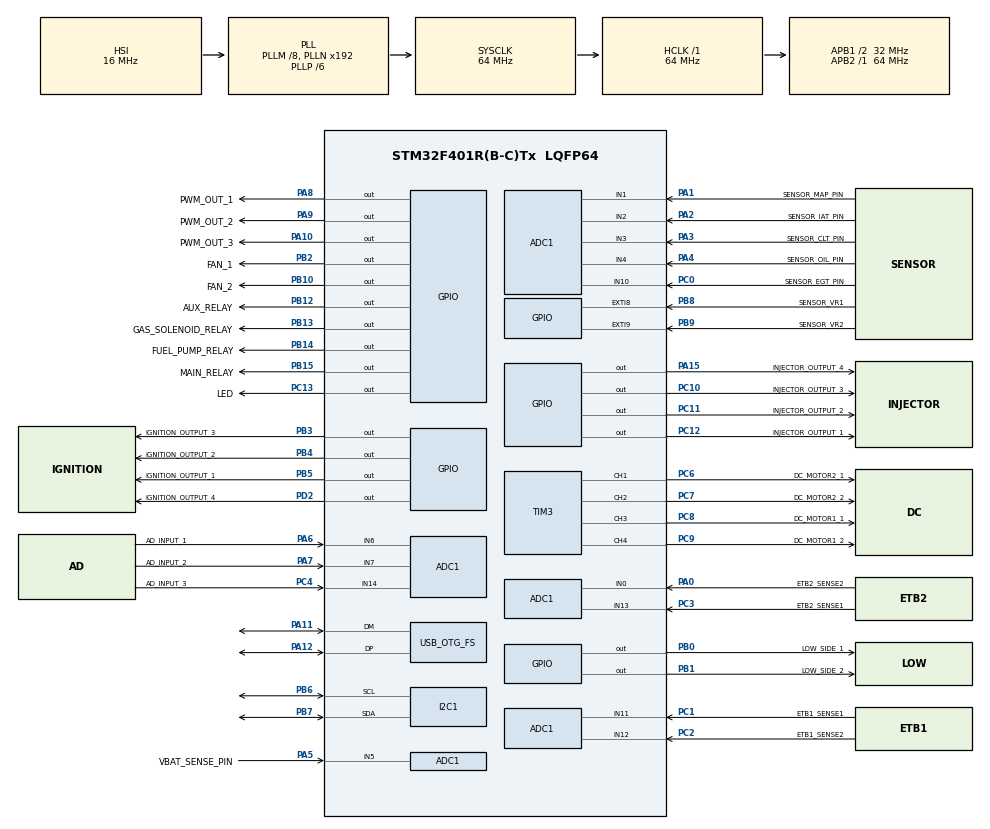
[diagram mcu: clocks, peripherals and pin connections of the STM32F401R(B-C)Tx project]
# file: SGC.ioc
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ADC1.Channel-10\#ChannelRegularConversion=ADC_CHANNEL_0
ADC1.Channel-11\#ChannelRegularConversion=ADC_CHANNEL_1
ADC1.Channel-12\#ChannelRegularConversion=ADC_CHANNEL_2
ADC1.Channel-13\#ChannelRegularConversion=ADC_CHANNEL_3
ADC1.Channel-14\#ChannelRegularConversion=ADC_CHANNEL_4
ADC1.Channel-15\#ChannelRegularConversion=ADC_CHANNEL_5
ADC1.Channel-16\#ChannelRegularConversion=ADC_CHANNEL_6
ADC1.Channel-17\#ChannelRegularConversion=ADC_CHANNEL_7
ADC1.Channel-18\#ChannelRegularConversion=ADC_CHANNEL_14
ADC1.Channel-19\#ChannelInjectedConversion=ADC_CHANNEL_11
ADC1.Channel-20\#ChannelInjectedConversion=ADC_CHANNEL_12
ADC1.Channel-21\#ChannelInjectedConversion=ADC_CHANNEL_13
ADC1.Channel-22\#ChannelInjectedConversion=ADC_CHANNEL_0
ADC1.Channel-4\#ChannelRegularConversion=ADC_CHANNEL_10
ADC1.Channel-5\#ChannelRegularConversion=ADC_CHANNEL_11
ADC1.Channel-6\#ChannelRegularConversion=ADC_CHANNEL_12
ADC1.Channel-7\#ChannelRegularConversion=ADC_CHANNEL_13
ADC1.ContinuousConvMode=DISABLE
ADC1.DMAContinuousRequests=ENABLE
ADC1.EOCSelection=ADC_EOC_SEQ_CONV
ADC1.EnableAnalogWatchDog=false
ADC1.ExternalTrigConv=ADC_EXTERNALTRIGCONV_T5_CC1
ADC1.ExternalTrigInjecConv=ADC_INJECTED_SOFTWARE_START
ADC1.InjNumberOfConversion=4
ADC1.InjectedConvMode=AutoInjected
ADC1.InjectedOffset-19\#ChannelInjectedConversion=0
ADC1.InjectedOffset-20\#ChannelInjectedConversion=0
ADC1.InjectedOffset-21\#ChannelInjectedConversion=0
ADC1.InjectedOffset-22\#ChannelInjectedConversion=0
ADC1.InjectedRank-19\#ChannelInjectedConversion=1
ADC1.InjectedRank-20\#ChannelInjectedConversion=2
ADC1.InjectedRank-21\#ChannelInjectedConversion=3
ADC1.InjectedRank-22\#ChannelInjectedConversion=4
ADC1.NbrOfConversion=13
ADC1.NbrOfConversionFlag=1
ADC1.Rank-10\#ChannelRegularConversion=5
ADC1.Rank-11\#ChannelRegularConversion=6
ADC1.Rank-12\#ChannelRegularConversion=7
ADC1.Rank-13\#ChannelRegularConversion=8
ADC1.Rank-14\#ChannelRegularConversion=9
ADC1.Rank-15\#ChannelRegularConversion=10
ADC1.Rank-16\#ChannelRegularConversion=11
ADC1.Rank-17\#ChannelRegularConversion=12
ADC1.Rank-18\#ChannelRegularConversion=13
ADC1.Rank-4\#ChannelRegularConversion=1
ADC1.Rank-5\#ChannelRegularConversion=2
ADC1.Rank-6\#ChannelRegularConversion=3
ADC1.Rank-7\#ChannelRegularConversion=4
ADC1.SamplingTime-10\#ChannelRegularConversion=ADC_SAMPLETIME_3CYCLES
ADC1.SamplingTime-11\#ChannelRegularConversion=ADC_SAMPLETIME_3CYCLES
ADC1.SamplingTime-12\#ChannelRegularConversion=ADC_SAMPLETIME_3CYCLES
ADC1.SamplingTime-13\#ChannelRegularConversion=ADC_SAMPLETIME_3CYCLES
ADC1.SamplingTime-14\#ChannelRegularConversion=ADC_SAMPLETIME_3CYCLES
ADC1.SamplingTime-15\#ChannelRegularConversion=ADC_SAMPLETIME_3CYCLES
ADC1.SamplingTime-16\#ChannelRegularConversion=ADC_SAMPLETIME_3CYCLES
ADC1.SamplingTime-17\#ChannelRegularConversion=ADC_SAMPLETIME_3CYCLES
ADC1.SamplingTime-18\#ChannelRegularConversion=ADC_SAMPLETIME_3CYCLES
ADC1.SamplingTime-19\#ChannelInjectedConversion=ADC_SAMPLETIME_3CYCLES
ADC1.SamplingTime-20\#ChannelInjectedConversion=ADC_SAMPLETIME_3CYCLES
ADC1.SamplingTime-21\#ChannelInjectedConversion=ADC_SAMPLETIME_3CYCLES
ADC1.SamplingTime-22\#ChannelInjectedConversion=ADC_SAMPLETIME_3CYCLES
ADC1.SamplingTime-4\#ChannelRegularConversion=ADC_SAMPLETIME_84CYCLES
ADC1.SamplingTime-5\#ChannelRegularConversion=ADC_SAMPLETIME_3CYCLES
ADC1.SamplingTime-6\#ChannelRegularConversion=ADC_SAMPLETIME_3CYCLES
ADC1.SamplingTime-7\#ChannelRegularConversion=ADC_SAMPLETIME_3CYCLES
ADC1.master=1
Dma.ADC1.0.Direction=DMA_PERIPH_TO_MEMORY
Dma.ADC1.0.FIFOMode=DMA_FIFOMODE_DISABLE
Dma.ADC1.0.Instance=DMA2_Stream0
Dma.ADC1.0.MemDataAlignment=DMA_MDATAALIGN_HALFWORD
Dma.ADC1.0.MemInc=DMA_MINC_ENABLE
Dma.ADC1.0.Mode=DMA_CIRCULAR
Dma.ADC1.0.PeriphDataAlignment=DMA_PDATAALIGN_HALFWORD
Dma.ADC1.0.PeriphInc=DMA_PINC_DISABLE
Dma.ADC1.0.Priority=DMA_PRIORITY_HIGH
Dma.Request0=ADC1
FREERTOS.Events01=engine_flags,Static,engine_flagsControlBlock
FREERTOS.Tasks01=defaultTask,48,512,StartDefaultTask,Default,NULL,Dynamic,NULL,NULL;init_task,48,1024,controller_init_task,Default,NULL,Dynamic,NULL,NULL
FREERTOS.configENABLE_FPU=1
Mcu.Family=STM32F4
Mcu.Name=STM32F401R(B-C)Tx
Mcu.Package=LQFP64
NVIC.DMA2_Stream0_IRQn=true\:7\:0\:true\:false\:true\:true\:false\:true\:true
NVIC.EXTI9_5_IRQn=true\:5\:0\:true\:false\:true\:true\:true\:true\:true
NVIC.OTG_FS_IRQn=true\:7\:0\:true\:false\:true\:true\:false\:true\:true
NVIC.PriorityGroup=NVIC_PRIORITYGROUP_4
NVIC.TIM1_TRG_COM_TIM11_IRQn=true\:15\:0\:false\:false\:true\:false\:false\:true\:true
NVIC.TIM2_IRQn=true\:6\:0\:true\:false\:true\:true\:true\:true\:true
NVIC.TimeBase=TIM1_TRG_COM_TIM11_IRQn
NVIC.TimeBaseIP=TIM11
PA0-WKUP.GPIO_Label=ETB2_SENSE2
PA0-WKUP.Signal=ADCx_IN0
PA1.GPIO_Label=SENSOR_MAP_PIN
PA1.Signal=ADCx_IN1
PA10.GPIO_Label=PWM_OUT_3
PA10.Signal=GPIO_Output
PA11.Mode=Device_Only
PA11.Signal=USB_OTG_FS_DM
PA12.Mode=Device_Only
PA12.Signal=USB_OTG_FS_DP
PA13.Mode=Serial_Wire
PA13.Signal=SYS_JTMS-SWDIO
PA14.Mode=Serial_Wire
PA14.Signal=SYS_JTCK-SWCLK
PA15.GPIO_Label=INJECTOR_OUTPUT_4
PA15.GPIO_PuPd=GPIO_NOPULL
PA15.GPIO_Speed=GPIO_SPEED_FREQ_MEDIUM
PA15.PinState=GPIO_PIN_RESET
PA15.Signal=GPIO_Output
PA2.GPIO_Label=SENSOR_IAT_PIN
PA2.Signal=ADCx_IN2
PA3.GPIO_Label=SENSOR_CLT_PIN
PA3.Signal=ADCx_IN3
PA4.GPIO_Label=SENSOR_OIL_PIN
PA4.Signal=ADCx_IN4
PA5.GPIO_Label=VBAT_SENSE_PIN
PA5.Signal=ADCx_IN5
PA6.GPIO_Label=AD_INPUT_1
PA6.Signal=ADCx_IN6
PA7.GPIO_Label=AD_INPUT_2
PA7.Signal=ADCx_IN7
PA8.GPIO_Label=PWM_OUT_1
PA8.Signal=GPIO_Output
PA9.GPIO_Label=PWM_OUT_2
PA9.Signal=GPIO_Output
PB0.GPIO_Label=LOW_SIDE_1
PB0.Signal=GPIO_Output
PB1.GPIO_Label=LOW_SIDE_2
PB1.Signal=GPIO_Output
PB10.GPIO_Label=FAN_2
PB10.Signal=GPIO_Output
PB12.GPIO_Label=AUX_RELAY
PB12.Signal=GPIO_Output
PB13.GPIO_Label=GAS_SOLENOID_RELAY
PB13.Signal=GPIO_Output
PB14.GPIO_Label=FUEL_PUMP_RELAY
PB14.Signal=GPIO_Output
PB15.GPIO_Label=MAIN_RELAY
PB15.Signal=GPIO_Output
PB2.GPIO_Label=FAN_1
PB2.Signal=GPIO_Output
PB3.GPIO_Label=IGNITION_OUTPUT_3
PB3.Signal=GPIO_Output
PB4.GPIO_Label=IGNITION_OUTPUT_2
PB4.Signal=GPIO_Output
PB5.GPIO_Label=IGNITION_OUTPUT_1
PB5.Signal=GPIO_Output
PB6.Mode=I2C
PB6.Signal=I2C1_SCL
PB7.Mode=I2C
PB7.Signal=I2C1_SDA
PB8.GPIO_Label=SENSOR_VR1
PB8.GPIO_ModeDefaultEXTI=GPIO_MODE_IT_RISING_FALLING
PB8.GPIO_PuPd=GPIO_NOPULL
PB8.Signal=GPXTI8
PB9.GPIO_Label=SENSOR_VR2
PB9.GPIO_ModeDefaultEXTI=GPIO_MODE_IT_RISING_FALLING
PB9.GPIO_PuPd=GPIO_NOPULL
PB9.Signal=GPXTI9
PC0.GPIO_Label=SENSOR_EGT_PIN
PC0.Signal=ADCx_IN10
PC1.GPIO_Label=ETB1_SENSE1
PC1.Signal=ADCx_IN11
PC10.GPIO_Label=INJECTOR_OUTPUT_3
PC10.Signal=GPIO_Output
PC11.GPIO_Label=INJECTOR_OUTPUT_2
PC11.Signal=GPIO_Output
PC12.GPIO_Label=INJECTOR_OUTPUT_1
PC12.Signal=GPIO_Output
PC13-ANTI_TAMP.GPIO_Label=LED
PC13-ANTI_TAMP.Signal=GPIO_Output
PC2.GPIO_Label=ETB1_SENSE2
PC2.Signal=ADCx_IN12
PC3.GPIO_Label=ETB2_SENSE1
PC3.Signal=ADCx_IN13
PC4.GPIO_Label=AD_INPUT_3
PC4.Signal=ADCx_IN14
PC6.GPIO_Label=DC_MOTOR2_1
PC6.Signal=S_TIM3_CH1
PC7.GPIO_Label=DC_MOTOR2_2
PC7.Signal=S_TIM3_CH2
PC8.GPIO_Label=DC_MOTOR1_1
PC8.Signal=S_TIM3_CH3
PC9.GPIO_Label=DC_MOTOR1_2
PC9.Signal=S_TIM3_CH4
PD2.GPIO_Label=IGNITION_OUTPUT_4
PD2.Signal=GPIO_Output
PH0\ -\ OSC_IN.Mode=HSE-External-Oscillator
PH0\ -\ OSC_IN.Signal=RCC_OSC_IN
PH1\ -\ OSC_OUT.Mode=HSE-External-Oscillator
PH1\ -\ OSC_OUT.Signal=RCC_OSC_OUT
ProjectManager.HeapSize=0x200
ProjectManager.StackSize=0x400
ProjectManager.TargetToolchain=Makefile
RCC.48MHZClocksFreq_Value=48000000
RCC.AHBFreq_Value=64000000
RCC.APB1CLKDivider=RCC_HCLK_DIV2
RCC.APB1Freq_Value=32000000
RCC.APB1TimFreq_Value=64000000
RCC.APB2Freq_Value=64000000
RCC.APB2TimFreq_Value=64000000
RCC.CortexFreq_Value=64000000
RCC.HCLKFreq_Value=64000000
RCC.HSE_VALUE=25000000
RCC.HSI_VALUE=16000000
RCC.LSE_VALUE=32768
RCC.PLLM=8
RCC.PLLP=RCC_PLLP_DIV6
RCC.PLLQ=8
RCC.PLLSource=RCC_PLLSOURCE_HSI
RCC.PLLSourceVirtualString=RCC_PLLSOURCE_HSI
RCC.SYSCLKFreq_VALUE=64000000
RCC.SYSCLKSource=RCC_SYSCLKSOURCE_PLLCLK
RCC.VCOOutputFreq_Value=384000000
SH.ADCx_IN0.0=ADC1_IN0,IN0
SH.ADCx_IN1.0=ADC1_IN1,IN1
SH.ADCx_IN10.0=ADC1_IN10,IN10
SH.ADCx_IN11.0=ADC1_IN11,IN11
SH.ADCx_IN12.0=ADC1_IN12,IN12
SH.ADCx_IN13.0=ADC1_IN13,IN13
SH.ADCx_IN14.0=ADC1_IN14,IN14
SH.ADCx_IN2.0=ADC1_IN2,IN2
SH.ADCx_IN3.0=ADC1_IN3,IN3
SH.ADCx_IN4.0=ADC1_IN4,IN4
SH.ADCx_IN5.0=ADC1_IN5,IN5
SH.ADCx_IN6.0=ADC1_IN6,IN6
SH.ADCx_IN7.0=ADC1_IN7,IN7
SH.S_TIM3_CH1.0=TIM3_CH1,PWM Generation1 CH1
SH.S_TIM3_CH2.0=TIM3_CH2,PWM Generation2 CH2
SH.S_TIM3_CH3.0=TIM3_CH3,PWM Generation3 CH3
SH.S_TIM3_CH4.0=TIM3_CH4,PWM Generation4 CH4
TIM2.Channel-Output\ Compare1\ No\ Output=TIM_CHANNEL_1
TIM2.OC1Preload=DISABLE
TIM2.Prescaler=84-1
TIM3.Channel-PWM\ Generation1\ CH1=TIM_CHANNEL_1
TIM3.Channel-PWM\ Generation2\ CH2=TIM_CHANNEL_2
TIM3.Channel-PWM\ Generation3\ CH3=TIM_CHANNEL_3
TIM3.Channel-PWM\ Generation4\ CH4=TIM_CHANNEL_4
TIM5.Channel-Output\ Compare1\ No\ Output=TIM_CHANNEL_1
TIM5.OC1Preload=ENABLE
TIM5.OCMode_1=TIM_OCMODE_TOGGLE
TIM5.Prescaler=64-1
TIM5.TIM_MasterOutputTrigger=TIM_TRGO_OC1REF
USB_DEVICE.CLASS_NAME_FS=CDC
USB_DEVICE.MANUFACTURER_STRING=Alireza Eskandari
USB_DEVICE.PRODUCT_STRING_CDC_FS=Smart Generator Controller
USB_DEVICE.VirtualMode=Cdc
USB_DEVICE.VirtualModeFS=Cdc_FS
USB_OTG_FS.VirtualMode=Device_Only
VP_CRC_VS_CRC.Mode=CRC_Activate
VP_FREERTOS_VS_CMSIS_V2.Mode=CMSIS_V2
VP_SYS_VS_tim11.Mode=TIM11
VP_TIM2_VS_ClockSourceINT.Mode=Internal
VP_TIM2_VS_no_output1.Mode=Output Compare1 No Output
VP_TIM3_VS_ClockSourceINT.Mode=Internal
VP_TIM5_VS_ClockSourceINT.Mode=Internal
VP_TIM5_VS_no_output1.Mode=Output Compare1 No Output
VP_USB_DEVICE_VS_USB_DEVICE_CDC_FS.Mode=CDC_FS
board=custom

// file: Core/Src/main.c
/* USER CODE BEGIN Header */
/**
  ******************************************************************************
  * @file           : main.c
  * @brief          : Main program body
  ******************************************************************************
  * @attention
  *
  * Copyright (c) 2025 STMicroelectronics.
  * All rights reserved.
  *
  * This software is licensed under terms that can be found in the LICENSE file
  * in the root directory of this software component.
  * If no LICENSE file comes with this software, it is provided AS-IS.
  *
  ******************************************************************************
  */
/* USER CODE END Header */
#include "main.h"
#include "cmsis_os.h"
#include "adc.h"
#include "crc.h"
#include "dma.h"
#include "i2c.h"
#include "tim.h"
#include "usb_device.h"
#include "gpio.h"

/* USER CODE BEGIN Includes */

#include "controller.h"

/* USER CODE END Includes */

void SystemClock_Config(void);
void MX_FREERTOS_Init(void);

int main(void)
{

  /* USER CODE BEGIN 1 */
  /**
   * @todo we will move to a proper init system in the future, but for now we are going to a simple methode for providing the settings
   */
  /* USER CODE END 1 */

  /* MCU Configuration--------------------------------------------------------*/

  /* Reset of all peripherals, Initializes the Flash interface and the Systick. */
  HAL_Init();

  /* Configure the system clock */
  SystemClock_Config();

  /* Initialize all configured peripherals */
  MX_GPIO_Init();
  MX_DMA_Init();
  MX_TIM3_Init();
  MX_ADC1_Init();
  MX_TIM2_Init();
  MX_CRC_Init();
  MX_I2C1_Init();
  MX_TIM5_Init();

  /* Init scheduler */
  osKernelInitialize();

  /* Call init function for freertos objects (in cmsis_os2.c) */
  MX_FREERTOS_Init();

  /* Start scheduler */
  osKernelStart();

  /* We should never get here as control is now taken by the scheduler */

  /* Infinite loop */
  while (1)
  {

  }
}

void SystemClock_Config(void)
{
  RCC_OscInitTypeDef RCC_OscInitStruct = {0};
  RCC_ClkInitTypeDef RCC_ClkInitStruct = {0};

  /** Configure the main internal regulator output voltage
  */
  __HAL_RCC_PWR_CLK_ENABLE();
  __HAL_PWR_VOLTAGESCALING_CONFIG(PWR_REGULATOR_VOLTAGE_SCALE2);

  /** Initializes the RCC Oscillators according to the specified parameters
  * in the RCC_OscInitTypeDef structure.
  */
  RCC_OscInitStruct.OscillatorType = RCC_OSCILLATORTYPE_HSI;
  RCC_OscInitStruct.HSIState = RCC_HSI_ON;
  RCC_OscInitStruct.HSICalibrationValue = RCC_HSICALIBRATION_DEFAULT;
  RCC_OscInitStruct.PLL.PLLState = RCC_PLL_ON;
  RCC_OscInitStruct.PLL.PLLSource = RCC_PLLSOURCE_HSI;
  RCC_OscInitStruct.PLL.PLLM = 8;
  RCC_OscInitStruct.PLL.PLLN = 192;
  RCC_OscInitStruct.PLL.PLLP = RCC_PLLP_DIV6;
  RCC_OscInitStruct.PLL.PLLQ = 8;
  if (HAL_RCC_OscConfig(&RCC_OscInitStruct) != HAL_OK)
  {
    Error_Handler();
  }

  /** Initializes the CPU, AHB and APB buses clocks
  */
  RCC_ClkInitStruct.ClockType = RCC_CLOCKTYPE_HCLK|RCC_CLOCKTYPE_SYSCLK
                              |RCC_CLOCKTYPE_PCLK1|RCC_CLOCKTYPE_PCLK2;
  RCC_ClkInitStruct.SYSCLKSource = RCC_SYSCLKSOURCE_PLLCLK;
  RCC_ClkInitStruct.AHBCLKDivider = RCC_SYSCLK_DIV1;
  RCC_ClkInitStruct.APB1CLKDivider = RCC_HCLK_DIV2;
  RCC_ClkInitStruct.APB2CLKDivider = RCC_HCLK_DIV1;

  if (HAL_RCC_ClockConfig(&RCC_ClkInitStruct, FLASH_LATENCY_2) != HAL_OK)
  {
    Error_Handler();
  }
}

void HAL_TIM_PeriodElapsedCallback(TIM_HandleTypeDef *htim)
{
  if (htim->Instance == TIM11)
  {
    HAL_IncTick();
  }
}

void Error_Handler(void)
{
  __disable_irq();
  while (1)
  {
  }
}

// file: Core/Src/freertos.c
/* USER CODE BEGIN Header */
/**
  ******************************************************************************
  * File Name          : freertos.c
  * Description        : Code for freertos applications
  ******************************************************************************
  * @attention
  *
  * Copyright (c) 2025 STMicroelectronics.
  * All rights reserved.
  *
  * This software is licensed under terms that can be found in the LICENSE file
  * in the root directory of this software component.
  * If no LICENSE file comes with this software, it is provided AS-IS.
  *
  ******************************************************************************
  */
/* USER CODE END Header */

#include "FreeRTOS.h"
#include "task.h"
#include "main.h"
#include "cmsis_os.h"

/* USER CODE BEGIN Includes */
#include "controller.h"
#include "trigger_simulator.h"
#include "utils.h"
/* USER CODE END Includes */

typedef StaticEventGroup_t osStaticEventGroupDef_t;

/* USER CODE BEGIN Variables */

table_2d_t test_table = {0};
float table_value = 0.0f;
/* USER CODE END Variables */
/* Definitions for defaultTask */
osThreadId_t defaultTaskHandle;
const osThreadAttr_t defaultTask_attributes = {
  .name = "defaultTask",
  .stack_size = 512 * 4,
  .priority = (osPriority_t) osPriorityRealtime,
};
/* Definitions for init_task */
osThreadId_t init_taskHandle;
const osThreadAttr_t init_task_attributes = {
  .name = "init_task",
  .stack_size = 1024 * 4,
  .priority = (osPriority_t) osPriorityRealtime,
};
/* Definitions for engine_flags */
osEventFlagsId_t engine_flagsHandle;
osStaticEventGroupDef_t engine_flagsControlBlock;
const osEventFlagsAttr_t engine_flags_attributes = {
  .name = "engine_flags",
  .cb_mem = &engine_flagsControlBlock,
  .cb_size = sizeof(engine_flagsControlBlock),
};

/* USER CODE BEGIN FunctionPrototypes */

void toggle_led();

/* USER CODE END FunctionPrototypes */

void StartDefaultTask(void *argument);
void controller_init_task(void *argument);

extern void MX_USB_DEVICE_Init(void);
void MX_FREERTOS_Init(void); /* (MISRA C 2004 rule 8.1) */

void MX_FREERTOS_Init(void) {

  /* Create the thread(s) */
  /* creation of defaultTask */
  defaultTaskHandle = osThreadNew(StartDefaultTask, NULL, &defaultTask_attributes);

  /* creation of init_task */
  init_taskHandle = osThreadNew(controller_init_task, NULL, &init_task_attributes);

  /* Create the event(s) */
  /* creation of engine_flags */
  engine_flagsHandle = osEventFlagsNew(&engine_flags_attributes);

}

void StartDefaultTask(void *argument)
{
  /* init code for USB_DEVICE */
  MX_USB_DEVICE_Init();
  /* USER CODE BEGIN StartDefaultTask */

  osDelay(100);

  /* Infinite loop */
  for(;;)
  {

    osDelay(1);
  }
  /* USER CODE END StartDefaultTask */
}

void controller_init_task(void *argument)
{
  /* USER CODE BEGIN controller_init_task */

  controller_init();

  /* Infinite loop */
  for(;;)
  {
    osDelay(100);

  }
  /* USER CODE END controller_init_task */
}

/* USER CODE BEGIN Application */
void toggle_led()
{
  HAL_GPIO_TogglePin(LED_GPIO_Port, LED_Pin);
}
/* USER CODE END Application */
